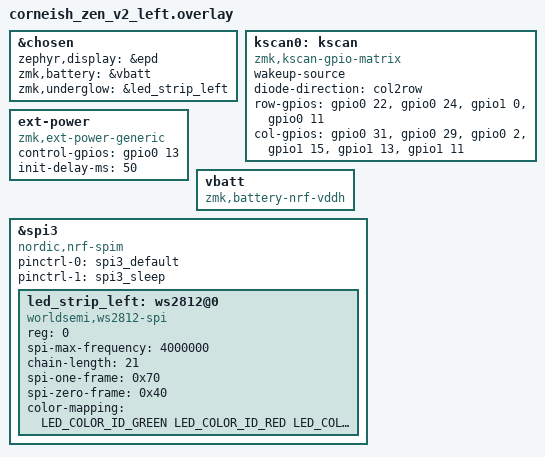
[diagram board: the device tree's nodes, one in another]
/*
* Left side overlay for Corne-ish Zen v2
* 21 LEDs (left half)
*/
#include "corneish_zen.dtsi"
#include <dt-bindings/led/led.h>

&chosen {
    zephyr,display = &epd;
    zmk,battery = &vbatt;
    zmk,underglow = &led_strip_left;
};

kscan0: kscan {
    compatible = "zmk,kscan-gpio-matrix";
    wakeup-source;
    diode-direction = "col2row";

    row-gpios = <&gpio0 22 (GPIO_ACTIVE_HIGH | GPIO_PULL_DOWN)>,
                <&gpio0 24 (GPIO_ACTIVE_HIGH | GPIO_PULL_DOWN)>,
                <&gpio1 0 (GPIO_ACTIVE_HIGH | GPIO_PULL_DOWN)>,
                <&gpio0 11 (GPIO_ACTIVE_HIGH | GPIO_PULL_DOWN)>;

    col-gpios = <&gpio0 31 GPIO_ACTIVE_HIGH>,
                <&gpio0 29 GPIO_ACTIVE_HIGH>,
                <&gpio0 2 GPIO_ACTIVE_HIGH>,
                <&gpio1 15 GPIO_ACTIVE_HIGH>,
                <&gpio1 13 GPIO_ACTIVE_HIGH>,
                <&gpio1 11 GPIO_ACTIVE_HIGH>;
};

ext-power {
    compatible = "zmk,ext-power-generic";
    control-gpios = <&gpio0 13 GPIO_ACTIVE_HIGH>;
    init-delay-ms = <50>;
};

vbatt: vbatt {
    compatible = "zmk,battery-nrf-vddh";
};

&spi3 {
    compatible = "nordic,nrf-spim";
    status = "okay";
    pinctrl-0 = <&spi3_default>;
    pinctrl-1 = <&spi3_sleep>;
    pinctrl-names = "default", "sleep";

    led_strip_left: ws2812@0 {
        compatible = "worldsemi,ws2812-spi";
        reg = <0>;
        spi-max-frequency = <4000000>;
        chain-length = <21>;    // Left half
        spi-one-frame = <0x70>;
        spi-zero-frame = <0x40>;
        color-mapping = <LED_COLOR_ID_GREEN LED_COLOR_ID_RED LED_COLOR_ID_BLUE>;
    };
};
